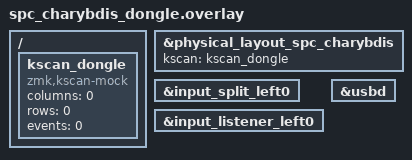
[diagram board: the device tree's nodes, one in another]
#include "spc_charybdis.dtsi"

/ {
    kscan_dongle: kscan_dongle {
        compatible = "zmk,kscan-mock";
        columns = <0>;
        rows = <0>;
        events = <0>;
    };
};

&physical_layout_spc_charybdis {
    kscan = <&kscan_dongle>;
};
// == Input devices ==
// Input devices on peripheral parts
// Enabling input listeners and input-split to receive input events from peripherals
&input_split_left0 { status = "okay"; };
&input_listener_left0 { status = "okay"; };

zephyr_udc0: &usbd {
    status = "okay";
};
